AUTOSAR XML (schema 00048)
standard types defined: boolean, sint16, uint16, uint8
package /VehicleProject
  system System
package /Cluster
  can cluster CAN00: protocol-name=CAN  # CANFD364
    can physical channel CHNL: comm-connectors=CN_CAN00
      frame msg_MyECU_Lamp_oCAN00: id 0x511, from MyECU, frame-length=32, can-addressing-mode=STANDARD, can-frame-rx-behavior=ANY, can-frame-tx-behavior=CAN-FD  # Motor FOC diagnostic data. MotorFoc_Page selects Control (0xA0), PWM (0xA1), or ADC (0xA2) payload.
        multiplexed i pdu msg_MyECU_Lamp_oCAN00:
          length=32
          dynamic-part{segment-positions=[{segment-byte-order=little-endian, segment-length=32, segment-position=0}, {segment-byte-order=little-endian, segment-length=208, segment-position=48}], dynamic-part-alternatives=[{i-pdu=msg_MyECU_Lamp_MxA0_oCAN00, initial-dynamic-part=true, selector-field-code=160}, {i-pdu=msg_MyECU_Lamp_MxA1_oCAN00, initial-dynamic-part=false, selector-field-code=161}, {i-pdu=msg_MyECU_Lamp_MxA2_oCAN00, initial-dynamic-part=false, selector-field-code=162}]}
          selector-field-byte-order=little-endian
          selector-field-length=8
          selector-field-start-position=0
          static-part{segment-position{segment-byte-order=little-endian, segment-length=16, segment-position=32}, i-pdu=msg_MyECU_Lamp_Mx_oCAN00}
          unused-bit-pattern=0
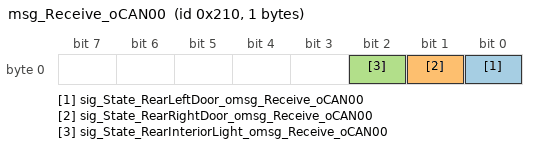
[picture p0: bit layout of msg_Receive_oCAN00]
      frame msg_Receive_oCAN00: id 0x210, to MyECU, frame-length=1, can-addressing-mode=STANDARD, can-frame-rx-behavior=ANY, can-frame-tx-behavior=CAN-20
        pdu msg_Receive_oCAN00: length=1, minimum-delay=0, transmission-mode-false-timing=cyclic-timing={time-offset=0, time-period=0.1}, transmission-mode-true-timing=cyclic-timing={time-offset=0, time-period=0.1}, unused-bit-pattern=0
          signal sig_State_RearLeftDoor_omsg_Receive_oCAN00: start 0, 1 bit, little-endian, i-signal-type=PRIMITIVE, init-value=0, base-type=boolean, compu {identical}, range raw 0..1, transfer-property=PENDING, to MyECU
          signal sig_State_RearRightDoor_omsg_Receive_oCAN00: start 1, 1 bit, little-endian, i-signal-type=PRIMITIVE, init-value=0, base-type=boolean, compu {identical}, range raw 0..1, transfer-property=PENDING, to MyECU
          signal sig_State_RearInteriorLight_omsg_Receive_oCAN00: start 2, 1 bit, little-endian, i-signal-type=PRIMITIVE, init-value=0, base-type=boolean, compu {identical}, range raw 0..1, transfer-property=PENDING, to MyECU
      frame msg_Transmit_oCAN00: id 0x200, from MyECU, frame-length=1, can-addressing-mode=STANDARD, can-frame-rx-behavior=ANY, can-frame-tx-behavior=CAN-20
        pdu msg_Transmit_oCAN00: length=1, minimum-delay=0, transmission-mode-false-timing=cyclic-timing={time-offset=0, time-period=0.1}, transmission-mode-true-timing=cyclic-timing={time-offset=0, time-period=0.1}, unused-bit-pattern=0
          signal sig_RearInteriorLight_omsg_Transmit_oCAN00: start 0, 1 bit, little-endian, i-signal-type=PRIMITIVE, init-value=0, base-type=boolean, compu {identical}, range raw 0..1, transfer-property=PENDING
      pdu triggering PT_msg_MyECU_Lamp_Mx: pdu=msg_MyECU_Lamp_Mx_oCAN00, from MyECU
      pdu triggering PT_msg_MyECU_Lamp_MxA{0..2}: pdu=msg_MyECU_Lamp_MxA{0..2}_oCAN00, from MyECU
package /ECU
  ecu instance MyECU: associated-com-i-pdu-group=[MyECU_oCAN00_Rx, MyECU_oCAN00_Tx]
    can communication controller CT_CAN00
    can communication connector CN_CAN00: comm-controller=CT_CAN00
package /IPDUGroup
  i signal i pdu group MyECU_oCAN00_Rx: communication-direction=IN, i-signal-i-pdus=msg_Receive_oCAN00
  i signal i pdu group MyECU_oCAN00_Tx: communication-direction=OUT
    i-signal-i-pdus:
      msg_MyECU_Lamp_Mx_oCAN00
      msg_MyECU_Lamp_MxA{0..2}_oCAN00
      msg_Transmit_oCAN00
package /PDU
  pdu msg_MyECU_Lamp_Mx_oCAN00: length=32, minimum-delay=0, transmission-mode-true-timing=event-controlled-timing={number-of-repetitions=0, repetition-period=0}, unused-bit-pattern=0
    signal MotorFoc_Sequence_Mx_omsg_MyECU_Lamp_oCAN00: start 32, 16 bit, little-endian, i-signal-type=PRIMITIVE, init-value=0, base-type=uint16, compu {identical}, range raw 0..65535, transfer-property=TRIGGERED-WITHOUT-REPETITION
  pdu msg_MyECU_Lamp_MxA0_oCAN00: length=32, minimum-delay=0, transmission-mode-true-timing=cyclic-timing={time-offset=0, time-period=0.015}, unused-bit-pattern=0
    signal MotorFoc_Page_MxA0_omsg_MyECU_Lamp_oCAN00: start 0, 8 bit, little-endian, i-signal-type=PRIMITIVE, init-value=160, base-type=uint8, compu {160=CxA0_Control, 161=CxA1_Pwm, 162=CxA2_Adc}, range raw 0..255, transfer-property=PENDING
    signal MotorFoc_MotorMode_MxA0_omsg_MyECU_Lamp_oCAN00: start 8, 8 bit, little-endian, i-signal-type=PRIMITIVE, init-value=0, base-type=uint8, compu {0=Cx00_Idle, 1=Cx01_Stop, 2=Cx02_FocSpeed, 3=Cx03_FocCurrent, 4=Cx04_OpenLoop, 5=Cx05_Calibration, 6=Cx06_CalibrationErase}, range raw 0..255, transfer-property=PENDING
    signal MotorFoc_Fault_MxA0_omsg_MyECU_Lamp_oCAN00: start 16, 8 bit, little-endian, i-signal-type=PRIMITIVE, init-value=0, base-type=uint8, compu {identical}, range raw 0..1, transfer-property=PENDING
    signal MotorFoc_FaultReason_MxA0_omsg_MyECU_Lamp_oCAN00: start 24, 8 bit, little-endian, i-signal-type=PRIMITIVE, init-value=0, base-type=uint8, compu {0=Cx00_None, 1=Cx01_UnderVoltage, 2=Cx02_OverCurrent}, range raw 0..255, transfer-property=PENDING
    signal MotorFoc_IdRef_A_MxA0_omsg_MyECU_Lamp_oCAN00: start 48, 16 bit, little-endian, i-signal-type=PRIMITIVE, init-value=0, base-type=sint16, compu {phys=raw*0.01 for raw -32768..32767; unit A}, range raw -32768..32767, unit=A, transfer-property=PENDING
    signal MotorFoc_IqRef_A_MxA0_omsg_MyECU_Lamp_oCAN00: start 64, 16 bit, little-endian, i-signal-type=PRIMITIVE, init-value=0, base-type=sint16, compu {phys=raw*0.01 for raw -32768..32767; unit A}, range raw -32768..32767, unit=A, transfer-property=PENDING
    signal MotorFoc_Id_A_MxA0_omsg_MyECU_Lamp_oCAN00: start 80, 16 bit, little-endian, i-signal-type=PRIMITIVE, init-value=0, base-type=sint16, compu {phys=raw*0.01 for raw -32768..32767; unit A}, range raw -32768..32767, unit=A, transfer-property=PENDING
    signal MotorFoc_Iq_A_MxA0_omsg_MyECU_Lamp_oCAN00: start 96, 16 bit, little-endian, i-signal-type=PRIMITIVE, init-value=0, base-type=sint16, compu {phys=raw*0.01 for raw -32768..32767; unit A}, range raw -32768..32767, unit=A, transfer-property=PENDING
    signal MotorFoc_Iu_A_MxA0_omsg_MyECU_Lamp_oCAN00: start 112, 16 bit, little-endian, i-signal-type=PRIMITIVE, init-value=0, base-type=sint16, compu {phys=raw*0.01 for raw -32768..32767; unit A}, range raw -32768..32767, unit=A, transfer-property=PENDING
    signal MotorFoc_Iv_A_MxA0_omsg_MyECU_Lamp_oCAN00: start 128, 16 bit, little-endian, i-signal-type=PRIMITIVE, init-value=0, base-type=sint16, compu {phys=raw*0.01 for raw -32768..32767; unit A}, range raw -32768..32767, unit=A, transfer-property=PENDING
    signal MotorFoc_Iw_A_MxA0_omsg_MyECU_Lamp_oCAN00: start 144, 16 bit, little-endian, i-signal-type=PRIMITIVE, init-value=0, base-type=sint16, compu {phys=raw*0.01 for raw -32768..32767; unit A}, range raw -32768..32767, unit=A, transfer-property=PENDING
    signal MotorFoc_Vdc_V_MxA0_omsg_MyECU_Lamp_oCAN00: start 160, 16 bit, little-endian, i-signal-type=PRIMITIVE, init-value=0, base-type=sint16, compu {phys=raw*0.1 for raw -32768..32767; unit V}, range raw -32768..32767, unit=V, transfer-property=PENDING
    signal MotorFoc_AngleRaw_MxA0_omsg_MyECU_Lamp_oCAN00: start 176, 16 bit, little-endian, i-signal-type=PRIMITIVE, init-value=0, base-type=uint16, compu {identical}, range raw 0..65535, unit=count, transfer-property=PENDING
    signal MotorFoc_ElectricalAngle_rad_MxA0_omsg_MyECU_Lamp_oCAN00: start 192, 16 bit, little-endian, i-signal-type=PRIMITIVE, init-value=0, base-type=sint16, compu {phys=raw*0.001 for raw -32768..32767; unit rad}, range raw -32768..32767, unit=rad, transfer-property=PENDING
    signal MotorFoc_CurrentOffsetReady_MxA0_omsg_MyECU_Lamp_oCAN00: start 208, 8 bit, little-endian, i-signal-type=PRIMITIVE, init-value=0, base-type=uint8, compu {identical}, range raw 0..1, transfer-property=PENDING
    signal MotorFoc_CurrentOffsetSampleCount_MxA0_omsg_MyECU_Lamp_oCAN00: start 216, 8 bit, little-endian, i-signal-type=PRIMITIVE, init-value=0, base-type=uint8, compu {identical}, range raw 0..255, unit=sample, transfer-property=PENDING
    signal MotorFoc_MechanicalSpeed_rpm_MxA0_omsg_MyECU_Lamp_oCAN00: start 224, 16 bit, little-endian, i-signal-type=PRIMITIVE, init-value=0, base-type=sint16, compu {identical}, range raw -32768..32767, unit=rpm, transfer-property=PENDING
    signal MotorFoc_GateDriverState_MxA0_omsg_MyECU_Lamp_oCAN00: start 240, 8 bit, little-endian, i-signal-type=PRIMITIVE, init-value=0, base-type=uint8, compu {identical}, range raw 0..255, transfer-property=PENDING
    signal MotorFoc_GateDriverOutputEnabled_MxA0_omsg_MyECU_Lamp_oCAN00: start 248, 8 bit, little-endian, i-signal-type=PRIMITIVE, init-value=0, base-type=uint8, compu {identical}, range raw 0..1, transfer-property=PENDING
  pdu msg_MyECU_Lamp_MxA1_oCAN00: length=32, minimum-delay=0, transmission-mode-true-timing=cyclic-timing={time-offset=0.005, time-period=0.015}, unused-bit-pattern=0
    signal MotorFoc_Page_MxA1_omsg_MyECU_Lamp_oCAN00: start 0, 8 bit, little-endian, i-signal-type=PRIMITIVE, init-value=161, base-type=uint8, compu {160=CxA0_Control, 161=CxA1_Pwm, 162=CxA2_Adc}, range raw 0..255, transfer-property=PENDING
    signal MotorFoc_MotorModePwm_MxA1_omsg_MyECU_Lamp_oCAN00: start 8, 8 bit, little-endian, i-signal-type=PRIMITIVE, init-value=0, base-type=uint8, compu {0=Cx00_Idle, 1=Cx01_Stop, 2=Cx02_FocSpeed, 3=Cx03_FocCurrent, 4=Cx04_OpenLoop, 5=Cx05_Calibration, 6=Cx06_CalibrationErase}, range raw 0..255, transfer-property=PENDING
    signal MotorFoc_FaultPwm_MxA1_omsg_MyECU_Lamp_oCAN00: start 16, 8 bit, little-endian, i-signal-type=PRIMITIVE, init-value=0, base-type=uint8, compu {identical}, range raw 0..1, transfer-property=PENDING
    signal MotorFoc_FaultReasonPwm_MxA1_omsg_MyECU_Lamp_oCAN00: start 24, 8 bit, little-endian, i-signal-type=PRIMITIVE, init-value=0, base-type=uint8, compu {0=Cx00_None, 1=Cx01_UnderVoltage, 2=Cx02_OverCurrent}, range raw 0..255, transfer-property=PENDING
    signal MotorFoc_VdRef_V_MxA1_omsg_MyECU_Lamp_oCAN00: start 48, 16 bit, little-endian, i-signal-type=PRIMITIVE, init-value=0, base-type=sint16, compu {phys=raw*0.001 for raw -32768..32767; unit V}, range raw -32768..32767, unit=V, transfer-property=PENDING
    signal MotorFoc_VqRef_V_MxA1_omsg_MyECU_Lamp_oCAN00: start 64, 16 bit, little-endian, i-signal-type=PRIMITIVE, init-value=0, base-type=sint16, compu {phys=raw*0.001 for raw -32768..32767; unit V}, range raw -32768..32767, unit=V, transfer-property=PENDING
    signal MotorFoc_ValphaRef_V_MxA1_omsg_MyECU_Lamp_oCAN00: start 80, 16 bit, little-endian, i-signal-type=PRIMITIVE, init-value=0, base-type=sint16, compu {phys=raw*0.001 for raw -32768..32767; unit V}, range raw -32768..32767, unit=V, transfer-property=PENDING
    signal MotorFoc_VbetaRef_V_MxA1_omsg_MyECU_Lamp_oCAN00: start 96, 16 bit, little-endian, i-signal-type=PRIMITIVE, init-value=0, base-type=sint16, compu {phys=raw*0.001 for raw -32768..32767; unit V}, range raw -32768..32767, unit=V, transfer-property=PENDING
    signal MotorFoc_PwmU_MxA1_omsg_MyECU_Lamp_oCAN00: start 112, 16 bit, little-endian, i-signal-type=PRIMITIVE, init-value=0, base-type=uint16, compu {identical}, range raw 0..65535, unit=tick, transfer-property=PENDING
    signal MotorFoc_PwmV_MxA1_omsg_MyECU_Lamp_oCAN00: start 128, 16 bit, little-endian, i-signal-type=PRIMITIVE, init-value=0, base-type=uint16, compu {identical}, range raw 0..65535, unit=tick, transfer-property=PENDING
    signal MotorFoc_PwmW_MxA1_omsg_MyECU_Lamp_oCAN00: start 144, 16 bit, little-endian, i-signal-type=PRIMITIVE, init-value=0, base-type=uint16, compu {identical}, range raw 0..65535, unit=tick, transfer-property=PENDING
    signal MotorFoc_PwmPeriod_MxA1_omsg_MyECU_Lamp_oCAN00: start 160, 16 bit, little-endian, i-signal-type=PRIMITIVE, init-value=0, base-type=uint16, compu {identical}, range raw 0..65535, unit=tick, transfer-property=PENDING
    signal MotorFoc_VdcMax_V_MxA1_omsg_MyECU_Lamp_oCAN00: start 176, 16 bit, little-endian, i-signal-type=PRIMITIVE, init-value=0, base-type=sint16, compu {phys=raw*0.1 for raw -32768..32767; unit V}, range raw -32768..32767, unit=V, transfer-property=PENDING
    signal MotorFoc_FaultIu_A_MxA1_omsg_MyECU_Lamp_oCAN00: start 192, 16 bit, little-endian, i-signal-type=PRIMITIVE, init-value=0, base-type=sint16, compu {phys=raw*0.01 for raw -32768..32767; unit A}, range raw -32768..32767, unit=A, transfer-property=PENDING
    signal MotorFoc_FaultIv_A_MxA1_omsg_MyECU_Lamp_oCAN00: start 208, 16 bit, little-endian, i-signal-type=PRIMITIVE, init-value=0, base-type=sint16, compu {phys=raw*0.01 for raw -32768..32767; unit A}, range raw -32768..32767, unit=A, transfer-property=PENDING
    signal MotorFoc_FaultIw_A_MxA1_omsg_MyECU_Lamp_oCAN00: start 224, 16 bit, little-endian, i-signal-type=PRIMITIVE, init-value=0, base-type=sint16, compu {phys=raw*0.01 for raw -32768..32767; unit A}, range raw -32768..32767, unit=A, transfer-property=PENDING
    signal MotorFoc_FaultVdc_V_MxA1_omsg_MyECU_Lamp_oCAN00: start 240, 16 bit, little-endian, i-signal-type=PRIMITIVE, init-value=0, base-type=sint16, compu {phys=raw*0.1 for raw -32768..32767; unit V}, range raw -32768..32767, unit=V, transfer-property=PENDING
  pdu msg_MyECU_Lamp_MxA2_oCAN00: length=32, minimum-delay=0, transmission-mode-true-timing=cyclic-timing={time-offset=0.01, time-period=0.015}, unused-bit-pattern=0
    signal MotorFoc_Page_MxA2_omsg_MyECU_Lamp_oCAN00: start 0, 8 bit, little-endian, i-signal-type=PRIMITIVE, init-value=162, base-type=uint8, compu {160=CxA0_Control, 161=CxA1_Pwm, 162=CxA2_Adc}, range raw 0..255, transfer-property=PENDING
    signal MotorFoc_AdcFilterEnabled_MxA2_omsg_MyECU_Lamp_oCAN00: start 8, 8 bit, little-endian, i-signal-type=PRIMITIVE, init-value=0, base-type=uint8, compu {identical}, range raw 0..1, transfer-property=PENDING
    signal MotorFoc_AdcFilterReady_MxA2_omsg_MyECU_Lamp_oCAN00: start 16, 8 bit, little-endian, i-signal-type=PRIMITIVE, init-value=0, base-type=uint8, compu {identical}, range raw 0..1, transfer-property=PENDING
    signal MotorFoc_AdcFilterAlpha_MxA2_omsg_MyECU_Lamp_oCAN00: start 24, 8 bit, little-endian, i-signal-type=PRIMITIVE, init-value=0, base-type=uint8, compu {phys=raw*0.01 for raw 0..100}, range raw 0..100, transfer-property=PENDING
    signal MotorFoc_IuRaw_A_MxA2_omsg_MyECU_Lamp_oCAN00: start 48, 16 bit, little-endian, i-signal-type=PRIMITIVE, init-value=0, base-type=sint16, compu {phys=raw*0.01 for raw -32768..32767; unit A}, range raw -32768..32767, unit=A, transfer-property=PENDING
    signal MotorFoc_IvRaw_A_MxA2_omsg_MyECU_Lamp_oCAN00: start 64, 16 bit, little-endian, i-signal-type=PRIMITIVE, init-value=0, base-type=sint16, compu {phys=raw*0.01 for raw -32768..32767; unit A}, range raw -32768..32767, unit=A, transfer-property=PENDING
    signal MotorFoc_IwRaw_A_MxA2_omsg_MyECU_Lamp_oCAN00: start 80, 16 bit, little-endian, i-signal-type=PRIMITIVE, init-value=0, base-type=sint16, compu {phys=raw*0.01 for raw -32768..32767; unit A}, range raw -32768..32767, unit=A, transfer-property=PENDING
    signal MotorFoc_IuFiltered_A_MxA2_omsg_MyECU_Lamp_oCAN00: start 96, 16 bit, little-endian, i-signal-type=PRIMITIVE, init-value=0, base-type=sint16, compu {phys=raw*0.01 for raw -32768..32767; unit A}, range raw -32768..32767, unit=A, transfer-property=PENDING
    signal MotorFoc_IvFiltered_A_MxA2_omsg_MyECU_Lamp_oCAN00: start 112, 16 bit, little-endian, i-signal-type=PRIMITIVE, init-value=0, base-type=sint16, compu {phys=raw*0.01 for raw -32768..32767; unit A}, range raw -32768..32767, unit=A, transfer-property=PENDING
    signal MotorFoc_IwFiltered_A_MxA2_omsg_MyECU_Lamp_oCAN00: start 128, 16 bit, little-endian, i-signal-type=PRIMITIVE, init-value=0, base-type=sint16, compu {phys=raw*0.01 for raw -32768..32767; unit A}, range raw -32768..32767, unit=A, transfer-property=PENDING
    signal MotorFoc_AdcOffsetVo1_MxA2_omsg_MyECU_Lamp_oCAN00: start 144, 16 bit, little-endian, i-signal-type=PRIMITIVE, init-value=0, base-type=sint16, compu {identical}, range raw -32768..32767, unit=count, transfer-property=PENDING
    signal MotorFoc_AdcOffsetVo2_MxA2_omsg_MyECU_Lamp_oCAN00: start 160, 16 bit, little-endian, i-signal-type=PRIMITIVE, init-value=0, base-type=sint16, compu {identical}, range raw -32768..32767, unit=count, transfer-property=PENDING
    signal MotorFoc_AdcOffsetVo3_MxA2_omsg_MyECU_Lamp_oCAN00: start 176, 16 bit, little-endian, i-signal-type=PRIMITIVE, init-value=0, base-type=sint16, compu {identical}, range raw -32768..32767, unit=count, transfer-property=PENDING
    signal MotorFoc_Vro_V_MxA2_omsg_MyECU_Lamp_oCAN00: start 192, 16 bit, little-endian, i-signal-type=PRIMITIVE, init-value=0, base-type=sint16, compu {phys=raw*0.001 for raw -32768..32767; unit V}, range raw -32768..32767, unit=V, transfer-property=PENDING
    signal MotorFoc_Vinv_V_MxA2_omsg_MyECU_Lamp_oCAN00: start 208, 16 bit, little-endian, i-signal-type=PRIMITIVE, init-value=0, base-type=sint16, compu {phys=raw*0.001 for raw -32768..32767; unit V}, range raw -32768..32767, unit=V, transfer-property=PENDING
    signal MotorFoc_AdcSyncCounter_MxA2_omsg_MyECU_Lamp_oCAN00: start 224, 16 bit, little-endian, i-signal-type=PRIMITIVE, init-value=0, base-type=uint16, compu {identical}, range raw 0..65535, unit=count, transfer-property=PENDING
    signal MotorFoc_AdcOffsetSampleCount_MxA2_omsg_MyECU_Lamp_oCAN00: start 240, 16 bit, little-endian, i-signal-type=PRIMITIVE, init-value=0, base-type=uint16, compu {identical}, range raw 0..65535, unit=sample, transfer-property=PENDING
package /DataType/Unit
  7 x unit:
    U_A: display-name=A
    U_count: display-name=count
    U_rad: display-name=rad
    U_rpm: display-name=rpm
    U_sample: display-name=sample
    U_tick: display-name=tick
    U_V: display-name=V
